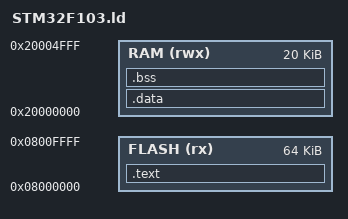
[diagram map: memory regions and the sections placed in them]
/* STM32F103C8T6 Linker Script (DUANYAN auto-generated) */
MEMORY
{
    FLASH (rx)  : ORIGIN = 0x08000000, LENGTH = 64K
    RAM   (rwx) : ORIGIN = 0x20000000, LENGTH = 20K
}

ENTRY(Reset_Handler)

SECTIONS
{
    .text : {
        KEEP(*(.isr_vector))
        *(.text*)
        *(.rodata*)
        . = ALIGN(4);
        _etext = .;
    } > FLASH

    .data : AT(_etext) {
        _sdata = .;
        *(.data*)
        . = ALIGN(4);
        _edata = .;
    } > RAM

    .bss : {
        _sbss = .;
        *(.bss*)
        *(COMMON)
        . = ALIGN(4);
        _ebss = .;
    } > RAM

    _stack_top = ORIGIN(RAM) + LENGTH(RAM);
}
